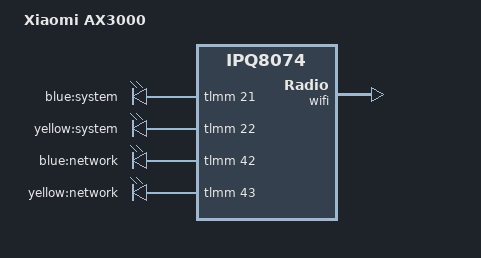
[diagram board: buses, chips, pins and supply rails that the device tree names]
// SPDX-License-Identifier: GPL-2.0-or-later OR MIT

/dts-v1/;

#include "ipq8071-ax3600.dts"

/ {
	model = "Xiaomi AX3000";
	compatible = "xiaomi,ax3000", "qcom,ipq8074";

	/delete-node/ leds;
	leds {
		compatible = "gpio-leds";
		led_system_blue: system-blue {
			label = "blue:system";
			gpios = <&tlmm 21 GPIO_ACTIVE_HIGH>;
		};

		led_system_yellow: system-yellow {
			label = "yellow:system";
			gpios = <&tlmm 22 GPIO_ACTIVE_HIGH>;
		};

		network-blue {
			label = "blue:network";
			gpios = <&tlmm 42 GPIO_ACTIVE_HIGH>;
		};
		network-yellow {
			label = "yellow:network";
			gpios = <&tlmm 43 GPIO_ACTIVE_HIGH>;
		};
	};
};

&pcie0 {
	status = "disabled";
};

&wifi {
	qcom,ath11k-calibration-variant = "Xiaomi-AX3000";
};
